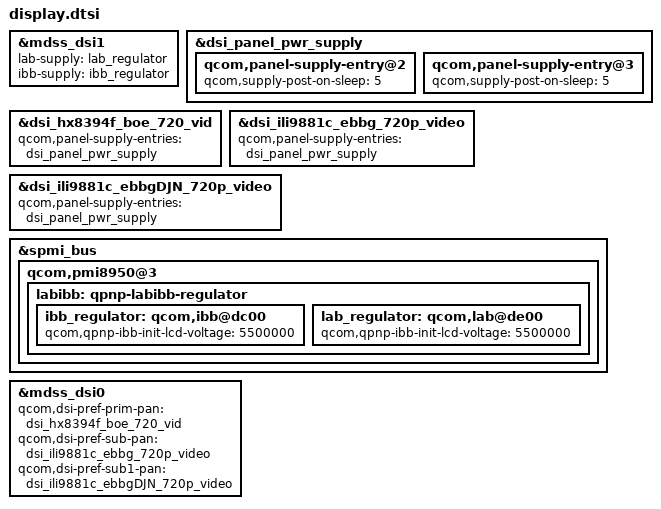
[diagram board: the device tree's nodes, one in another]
#include "panels/dsi-panel-hx8394f-boe-720p-video.dtsi"
#include "panels/dsi-panel-ili9881c-ebbg-720p-video.dtsi"
#include "panels/dsi-panel-ili9881c-ebbgDJN-720p-video.dtsi"

/* FROM: S88536AA2.dtsi */
&mdss_dsi1 {
	lab-supply = <&lab_regulator>;
	ibb-supply = <&ibb_regulator>;
};

&dsi_panel_pwr_supply {
	qcom,panel-supply-entry@2 {
		qcom,supply-post-on-sleep = <5>;
	};

	qcom,panel-supply-entry@3 {
		qcom,supply-post-on-sleep = <5>;
	};
};

&dsi_hx8394f_boe_720_vid {
	qcom,panel-supply-entries = <&dsi_panel_pwr_supply>;
};

&dsi_ili9881c_ebbg_720p_video {
	qcom,panel-supply-entries = <&dsi_panel_pwr_supply>;
};

&dsi_ili9881c_ebbgDJN_720p_video {
	qcom,panel-supply-entries = <&dsi_panel_pwr_supply>;
};

&spmi_bus {
	qcom,pmi8950@3 {
		labibb: qpnp-labibb-regulator {
			ibb_regulator: qcom,ibb@dc00 {
				qcom,qpnp-ibb-init-lcd-voltage = <5500000>;
			};

			lab_regulator: qcom,lab@de00 {
				qcom,qpnp-ibb-init-lcd-voltage = <5500000>;
			};
		};
	};
};

&mdss_dsi0 {
	qcom,dsi-pref-prim-pan = <&dsi_hx8394f_boe_720_vid>;
	qcom,dsi-pref-sub-pan = <&dsi_ili9881c_ebbg_720p_video>;
	qcom,dsi-pref-sub1-pan = <&dsi_ili9881c_ebbgDJN_720p_video>;
};
